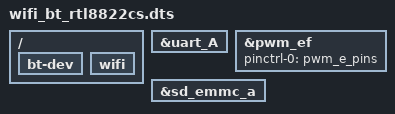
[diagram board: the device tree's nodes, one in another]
/dts-v1/;
/plugin/;

/{
	fragment@0 {
		target-path = "/";

		__overlay__ {
			bt-dev {
				status = "okay";
			};

			wifi {
				status = "okay";
			};
		};
	};

	fragment@1 {
		target = <&uart_A>;

		__overlay__ {
			status = "okay";
		};
	};

	fragment@2 {
		target = <&pwm_ef>;

		__overlay__ {
			status = "okay";
			pinctrl-names = "pwm_pins";
			pinctrl-0 = <&pwm_e_pins>;
		};
	};

	fragment@3 {
		target = <&sd_emmc_a>;

		__overlay__ {
			status = "okay";
		};
	};
};
